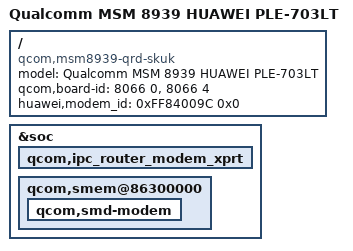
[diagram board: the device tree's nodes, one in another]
/* < DTS2015112007164 lwx247446 20151120 begin */
/* Copyright (c) 2015, The Linux Foundation. All rights reserved.
 *
 * This program is free software; you can redistribute it and/or modify
 * it under the terms of the GNU General Public License version 2 and
 * only version 2 as published by the Free Software Foundation.
 *
 * This program is distributed in the hope that it will be useful,
 * but WITHOUT ANY WARRANTY; without even the implied warranty of
 * MERCHANTABILITY or FITNESS FOR A PARTICULAR PURPOSE.  See the
 * GNU General Public License for more details.
 */

/dts-v1/;
#include "msm8939-v3.0.dtsi"
#include "msm8939-qrd-skuk.dtsi"
#include "pele/huawei_ple_703lt_va.dts"

/ {
	model = "Qualcomm MSM 8939 HUAWEI PLE-703LT";
	compatible = "qcom,msm8939-qrd-skuk", "qcom,msm8939", "qcom,qrd";
	qcom,board-id = <8066 0> , <8066 4>;
	huawei,modem_id = <0xFF84009C 0x0>;
};

&soc {
	qcom,ipc_router_modem_xprt {
		/delete-property/ qcom,disable-pil-loading;
	};

	qcom,smem@86300000 {
		qcom,smd-modem {
			/delete-property/ qcom,not-loadable;
		};
	};
};
